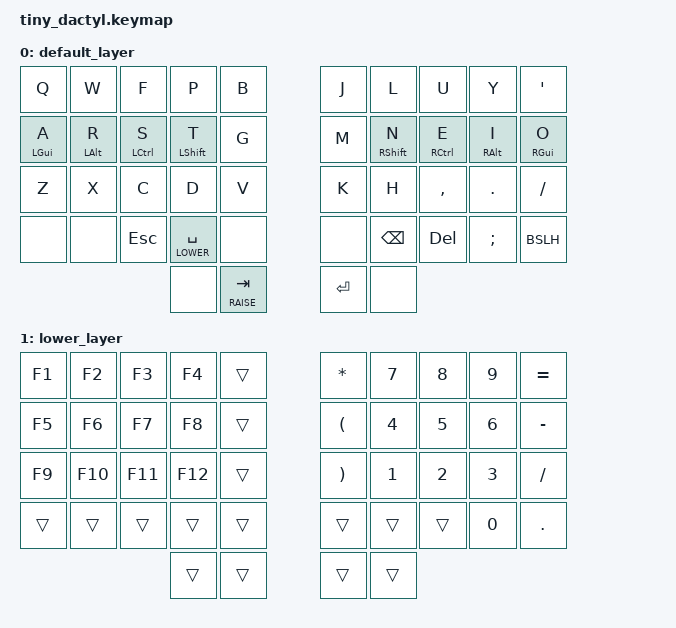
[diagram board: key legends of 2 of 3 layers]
/*
 * Copyright (c) 2020 The ZMK Contributors
 *
 * SPDX-License-Identifier: MIT
 */

#include <behaviors.dtsi>
#include <dt-bindings/zmk/keys.h>
#include <dt-bindings/zmk/bt.h>

/ {
    keymap {
        compatible = "zmk,keymap";

        
        default_layer {
// ------------------------------------------------------------------------------------------------------------
// |  Q    |   W   |   F    |    P   |   B   |                     |   J   |   L   |   U    |   Y   |   '   | 
// | A/gui | R/alt | S/Ctrl | T/shft |   G   |                     |   M   | N/shft| E/Ctrl | I/Alt | O/gui | 
// |  Z    |   X   |   C    |    D   |   V   |                     |   K   |   H   |    ,   |   .   |   /   |
//         |  xxx  |  xxx   |   Esc  |  Spc  |  xxx  |     |  xxx  |  bksp |  Del  |   ;    |   \   |
//                                   |  xxx  |  Tab  |     | Enter |  xxx  |                                                                                           |
//
            bindings = <
&kp Q       &kp W        &kp F         &kp P          &kp B                                         &kp J     &kp L         &kp U         &kp Y        &kp APOS
&mt LGUI A  &mt LALT R   &mt LCTRL S   &mt LSHFT T    &kp G                                         &kp M     &mt RSHFT N   &mt RCTRL E   &mt RALT I   &mt RGUI O
&kp Z       &kp X        &kp C         &kp D          &kp V                                         &kp K     &kp H         &kp COMMA     &kp DOT      &kp FSLH    
            &none        &none         &kp ESC        &lt LOWER SPACE  &none             &none      &kp BSPC  &kp DEL       &kp SEMI      &BSLH
                                                      &none            &lt RAISE TAB     &kp ENTER  &none   
            >;

            sensor-bindings = <&inc_dec_kp C_VOL_UP C_VOL_DN &inc_dec_kp PG_UP PG_DN>;
        };

        lower_layer {
// ------------------------------------------------------------------------------------------------------------
// |  F1 | F2  |  F3  |  F4  |      |                     |   *   |   7   |   8   |   9   |   =   |
// |  F5 | F6  |  F7  |  F8  |      |                     |   (   |   4   |   5   |   6   |   -   |
// |  F9 | F10 | F11  |  F12 |      |                     |   )   |   1   |   2   |   3   |   /   |
//       |     |      |      |      |  xxx  |     |  xxx  | bksp  |  Del  |   0   |   .   |       
//                           |  xxx | Lower |     |  Ent  |  xxx  |
            bindings = <
&kp F1    &kp F2    &kp F3    &kp F4    &trans                        &kp ASTRK  &kp N7    &kp N8    &kp N9   &kp EQUAL
&kp F5    &kp F6    &kp F7    &kp F8    &trans                        &kp LPAR   &kp N4    &kp N5    &kp N6   &kp MINUS
&kp F9    &kp F10   &kp F11   &kp F12   &trans                        &kp RPAR   &kp N1    &kp N2    &kp N3   &kp FSLH
          &trans    &trans    &trans    &trans    &trans    &trans    &trans     &trans    &kp N0    &kp DOT
                                        &trans    &trans    &trans    &trans   
            >;
        };

        raise_layer {
// ------------------------------------------------------------------------------------------------------------
// |  F1 | F2  |  F3  |  F4  |  F5  |                       |  F8   |  F9   |  F10  |  F11  |  F12  |
// |     |     |      |      |      |                       |       |       |   ^   |       |       |
// |     |     |      |      |      |                       |       |   <   |   v   |   >   |       |
//       |     |      |      |      |       |       |       |       |       |       |       |    
//                           |      |       |       |       |       |            

            bindings = <
&kp F1    &kp F2    &kp F3    &kp F4    &kp F5                           &kp F8    &kp F9    &kp F10  &kp F11   &kp F12  
&trans    &trans    &trans    &trans    &trans                           &none     &none     &kp UP   &none     &none    
&trans    &trans    &trans    &trans    &trans                           &none     &kp LEFT  &kp DOWN &kp RIGHT &none
&trans    &trans    &trans    &trans    &trans    &trans       &trans    &trans    &trans    &none    &none
                                        &trans    &trans       &trans    &trans     
            >;
        };
    };
};
